# T113-S3 register map
Vendor: Allwinner; Series: T113-S3; File version: 0.1
CPU: other 0, little endian, MPU, no FPU, 0 interrupt priority bits
Registers are 32-bit, read-write, reset 0x0 unless marked. A register's access mark holds for its fields unless they carry their own. Offsets are from the block's base; [hi:lo] are bit positions; {n}, {i} and the like mark numbered series; 'fields as' and 'values as' point back to an identical list.

## OWA
Base 0x02036000
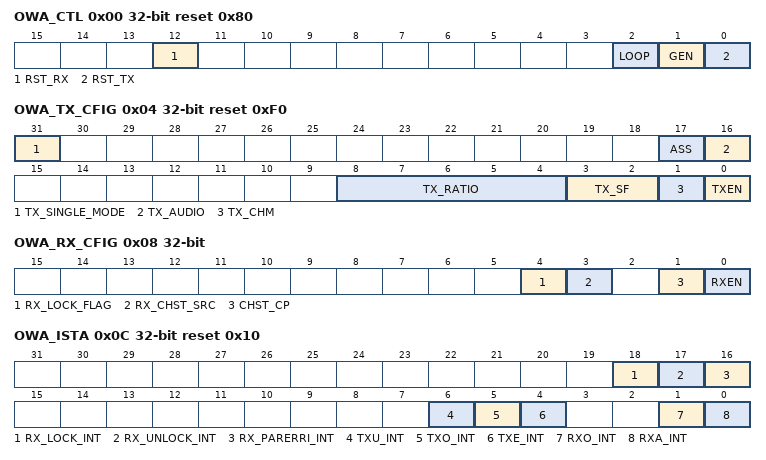
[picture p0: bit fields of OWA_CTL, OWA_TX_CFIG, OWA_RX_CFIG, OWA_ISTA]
0x00 OWA_CTL reset 0x80
  [12] RST_RX — Reset RX 0: Normal 1: Reset Self clear to `0`.
    0=Normal; 1=Reset Self clear to `0`
  [2] LOOP — Loopback Test 0: Normal Mode 1: Loopback Test When the bit is set to `1`, the DOUT and DIN need be connected.
    0=Normal Mode; 1=Loopback Test When the bit is set to `1`, the DOUT and DIN need be connected
  [1] GEN — Global Enable Disabling this bit overrides the operations of enabling and flushing all FIFOs by any other blocks or channels. 0: Disabled 1: Enabled
    0=Disabled; 1=Enabled
  [0] RST_TX — Reset TX 0: Normal 1: Reset Self clear to 0.
    0=Normal; 1=Reset Self clear to 0
0x04 OWA_TX_CFIG reset 0xF0 — OWA TX Configuration Register
  [31] TX_SINGLE_MODE — Tx Single Channel Mode 0: Disabled 1: Enabled
    0=Disabled; 1=Enabled
  [17] ASS — Audio Sample Select when TX FIFO Underrun 0: Sending 0 1: Sending the last audio
    0=Sending_0; 1=Sending the last audio
  [16] TX_AUDIO — TX Data Type 0: Linear PCM (Valid bit of both sub-frame set to 0 ) 1: Non-audio (Valid bit of both sub-frame set to 1)
    0=Linear PCM (Valid bit of both sub-frame set to 0 ); 1=Non-audio (Valid bit of both sub-frame set to 1)
  [8:4] TX_RATIO — TX Clock Divide Ratio Clock divide ratio = TX_TATIO + 1 Fs = PLL_AUDIO/[(TX_TATIO + 1)*64*2]
  [3:2] TX_SF — TX Sample Format 00: 16 bits 01: 20 bits 10: 24 bits 11: Reserved
    0=_16_bits; 1=_20_bits; 2=_24_bits
  [1] TX_CHM — CHSTMODE 0: Channel status A and B set to 0 1: Channel status A and B generated from TX_CHSTA
    0=Channel status A and B set to 0; 1=Channel status A and B generated from TX_CHSTA
  [0] TXEN — TX Enable 0: Disabled 1: Enabled
    0=Disabled; 1=Enabled
0x08 OWA_RX_CFIG — OWA RX Configuration Register
  [4] RX_LOCK_FLAG ro — RX Lock Flag 0: Unlocked 1: Locked
    0=Unlocked; 1=Locked
  [3] RX_CHST_SRC — RX Channel State Source Select 0: RX_CH_STA register holds status from Channel A 1: RX_CH_STA register holds status from Channel B
    0=RX_CH_STA_register_holds_status_from_Channel_A; 1=RX_CH_STA_register_holds_status_from_Channel_B
  [1] CHST_CP — Channel Status Capture 0: Idle or Capture End 1: Capture Channel Status Start The field must be set to 1 at each operation (such as recording). When set to `1`, the system starts to capture the channel status. When finished, the bit will automatically turn to `0`.
    0=Idle or Capture End; 1=Capture Channel Status Start The field must be set to 1 at each operation (such as recording). When set to `1`, the system starts to capture the channel status. When finished, the bit will automatically turn to `0`.
  [0] RXEN — 0: Disabled 1: Enabled
    0=Disabled; 1=Enabled
0x0C OWA_ISTA reset 0x10 — OWA Interrupt Status Register
  [18] RX_LOCK_INT write-1-clears — RX Lock Interrupt 0: No Pending IRQ 1: RX Lock Pending Interrupt (RX_LOCK_FLAG turns from 0 to 1) Write `1` to clear this interrupt.
    0=No Pending IRQ; 1=RX (RX Lock Pending Interrupt (RX_LOCK_FLAG turns from 0 to 1) Write `1` to clear this interrupt.)
  [17] RX_UNLOCK_INT write-1-clears — RX Unlock Pending Interrupt 0: No Pending IRQ 1: RX Unlock Pending Interrupt (RX_LOCK_FLAG turns from 0 to 1) Write 1 to clear this interrupt.
    0=No Pending IRQ; 1=RX (RX Unlock Pending Interrupt (RX_LOCK_FLAG turns from 0 to 1) Write 1 to clear this interrupt.)
  [16] RX_PARERRI_INT write-1-clears — RX Parity Error Pending Interrupt 0: No Pending IRQ 1: RX Parity Error Pending Interrupt Write `1` to clear this interrupt
    0=No Pending IRQ; 1=RX (RX Parity Error Pending Interrupt Write `1` to clear this interrupt)
  [6] TXU_INT write-1-clears — TX FIFO Underrun Pending Interrupt 0: No Pending IRQ 1: FIFO Underrun Pending Interrupt Writing `1` to clear this interrupt.
    0=No Pending IRQ; 1=FIFO (FIFO Underrun Pending Interrupt Writing `1` to clear this interrupt.)
  [5] TXO_INT write-1-clears — TX FIFO Overrun Pending Interrupt 0: No Pending IRQ 1: FIFO Overrun Pending Interrupt Writing `1` to clear this interrupt.
    0=No Pending IRQ; 1=FIFO (FIFO Overrun Pending Interrupt Writing `1` to clear this interrupt.)
  [4] TXE_INT write-1-clears — TX FIFO Empty Pending Interrupt 0: No Pending IRQ 1: FIFO Empty Pending Interrupt Writing `1` to clear this interrupt or automatically clear if the interrupt condition fails.
    0=No Pending IRQ; 1=FIFO (FIFO Empty Pending Interrupt Writing `1` to clear this interrupt or automatically clear if the interrupt condition fails.)
  [1] RXO_INT write-1-clears — RXFIFO Overrun Pending Interrupt 0: RXFIFO Overrun Pending Write `1` to clear this interrupt.
    0=RXFIFO (RXFIFO Overrun Pending Write `1` to clear this interrupt.)
  [0] RXA_INT write-1-clears — RXFIFO Available Pending Interrupt 0: No Pending IRQ 1: Data Available Pending IRQ Write `1` to clear this interrupt or automatically clear if the interrupt condition fails.
    0=No Pending IRQ; 1=Data Available Pending IRQ Write `1` to clear this interrupt or automatically clear if the interrupt condition fails
0x10 OWA_RXFIFO
  [31:0] RX_DATA ro — The host can get one sample by reading this register, A channel data is first, and then the B channel data.
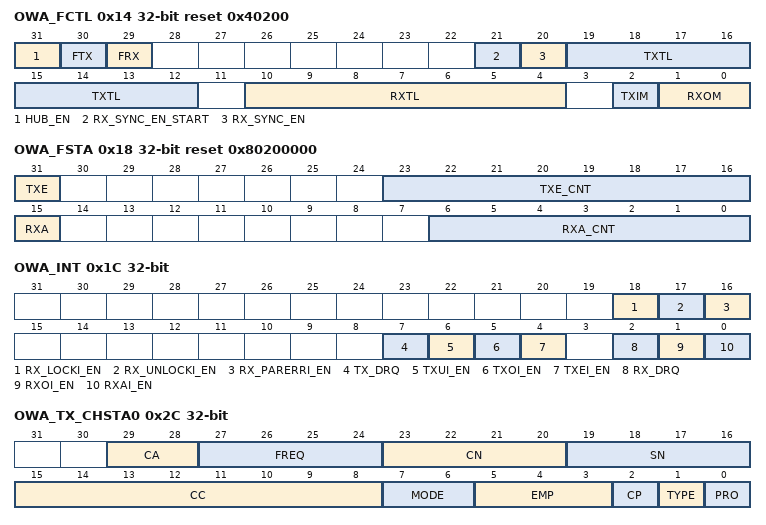
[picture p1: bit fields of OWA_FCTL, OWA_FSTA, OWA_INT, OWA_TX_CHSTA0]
0x14 OWA_FCTL reset 0x40200 — OWA FIFO Control Register
  [31] HUB_EN — Audio Hub Enable The bit takes effect only when the TXEN is set to 1. Audio codec/I2S1/I2S2/OWA TXFIFO Hub Enable. 0: Disabled 1: Enabled
    0=Disabled; 1=Enabled
  [30] FTX write-1-clears — Write `1` to flush TXFIFO, self clear to `0`.
  [29] FRX write-1-clears — Write `1` to flush RXFIFO, self clear to `0`.
  [21] RX_SYNC_EN_START — The bit takes effect only when the RX_SYNC_EN is set to 1. Audio Codec/I2S1/I2S2/DMIC/OWA RX Synchronize Enable Start. 0: Disabled 1: Enabled
    0=Disabled; 1=Enabled
  [20] RX_SYNC_EN — OWA RX Synchronize Enable 0: Disabled 1: Enabled
    0=Disabled; 1=Enabled
  [19:12] TXTL — TX FIFO Empty Trigger Level Interrupt and DMA request trigger level for TX FIFO normal condition. Trigger Level = TXTL
  [10:4] RXTL — RX FIFO Trigger Level Interrupt and DMA request trigger level for RX FIFO normal condition. Trigger Level = RXTL + 1
  [2] TXIM — TXFIFO Input Mode (Mode0, 1) 0: Valid data at the MSB of TXFIFO Register 1: Valid data at the LSB of TXFIFO Register Example for 20-bit transmitted audio sample: Mode 0: TXFIFO[23:0] = {APB_WDATA[31:12], 4`h0} Mode 1: TXFIFO[23:0] = {APB_WDATA[19:0], 4`h0}
    0=Valid data at the MSB of TXFIFO Register; 1=Valid data at the LSB of TXFIFO Register Example for 20-bit transmitted audio sample: Mode 0: TXFIFO[23:0] = {APB_WDATA[31:12], 4`h0} Mode 1: TXFIFO[23:0] = {APB_WDATA[19:0], 4`h0}
  [1:0] RXOM — RXFIFO Output Mode(Mode 0,1,2,3) 00: Expanding `0` at LSB of RXFIFO Register 01: Expanding received sample sign bit at MSB of RXFIFO Register 10: Truncating received samples at high half-word of RXFIFO Register and low half-word of RXFIFO Register is filled by `0` 11: Truncating received samples at low half-word of RXFIFO Register and high half-word of RXFIFO Register is expanded by its sigh bit Mode 0: APB_RDATA[31:0] = {RXFIFO[23:0], 8`h0} Mode 1: APB_RDATA[31:0] = {8`RXFIFO[23], RXFIFO[23:0]} Mode 2: APB_RDATA[31:0] = {RXFIFO[23:8], 16`h0} Mode 3: APB_RDATA[31:0] = {16`RXFIFO[23], RXFIFO[23:8]}
    0=Expanding `0` at LSB of RXFIFO Register; 1=Expanding received sample sign bit at MSB of RXFIFO Register; 2=Truncating received samples at high half-word of RXFIFO Register and low half-word of RXFIFO Register is filled by `0`; 3=Truncating received samples at low half-word of RXFIFO Register and high half-word of RXFIFO Register is expanded by its sigh bit Mode 0: APB_RDATA[31:0] = {RXFIFO[23:0], 8`h0} Mode 1: APB_RDATA[31:0] = {8`RXFIFO[23], RXFIFO[23:0]} Mode 2: APB_RDATA[31:0] = {RXFIFO[23:8], 16`h0} Mode 3: APB_RDATA[31:0] = {16`RXFIFO[23], RXFIFO[23:8]}
0x18 OWA_FSTA reset 0x80200000 — OWA FIFO Status Register
  [31] TXE ro — TXFIFO Empty (indicate the TXFIFO is not full) 0: No room for new sample in TXFIFO 1: More than one room for new sample in TXFIFO ( >= 1 Word )
    0=No room for new sample in TXFIFO; 1=More than one room for new sample in TXFIFO ( >= 1 Word )
  [23:16] TXE_CNT ro — TXFIFO Empty Space Word Counter
  [15] RXA ro — RXFIFO Available 0: No available data in RXFIFO 1: More than one sample in RXFIFO ( >= 1 Word )
    0=No available data in RXFIFO; 1=More than one sample in RXFIFO ( >= 1 Word )
  [6:0] RXA_CNT ro — RXFIFO Available Sample Word Counter
0x1C OWA_INT — OWA Interrupt Control Register
  [all] fields
    0=Disabled; 1=Enabled
  [18] RX_LOCKI_EN — RX LOCK Interrupt Enable 0: Disabled 1: Enabled
  [17] RX_UNLOCKI_EN — RX UNLOCK Interrupt Enable 0: Disabled 1: Enabled
  [16] RX_PARERRI_EN — RX PARITY ERORR Interrupt Enable 0: Disabled 1: Enabled
  [7] TX_DRQ — TXFIFO Empty DRQ Enable 0: Disabled 1: Enabled
  [6] TXUI_EN — TXFIFO Underrun Interrupt Enable 0: Disabled 1: Enabled
  [5] TXOI_EN — TXFIFO Overrun Interrupt Enable 0: Disabled 1: Enabled
  [4] TXEI_EN — TXFIFO Empty Interrupt Enable 0: Disabled 1: Enabled
  [2] RX_DRQ — RXFIFO Data Available DRQ Enable When set to `1`, RXFIFO DMA Request is asserted if data is available in RXFIFO. 0: Disabled 1: Enabled
  [1] RXOI_EN — RXFIFO Overrun Interrupt Enable 0: Disabled 1: Enabled
  [0] RXAI_EN — RXFIFO Data Available Interrupt Enable 0: Disabled 1: Enabled
0x20 OWA_TXFIFO
  [31:0] TX_DATA wo — Transmitting A, B channel data should be written this register one by one. A channel data is first, and then the B channel data.
0x24 OWA_TX_CNT — OWA TX Counter Register
  [31:0] TX_CNT — TX Sample Counter The audio sample number of sending into TXFIFO. When one sample is put into TXFIFO by DMA or by host IO, the TX sample counter register increases by one. The TX sample counter register can be set to any initial value at any time. After updated by the initial value, the counter register should count on the base of this initial value.
0x28 OWA_RX_CNT — OWA RX Counter Register
  [31:0] RX_CNT — RX Sample Counter The audio sample number of writing into RXFIFO. When one sample is written by Codec, the RX sample counter register increases by one. The RX counter register can be set to any initial value at any time. After being updated by the initial value, the counter register should count on the base of this value.
0x2C OWA_TX_CHSTA0 — OWA TX Channel Status Register0
  [29:28] CA — Clock Accuracy 00: Level 2 01: Level 1 10: Level 3 11: Not matched
    0=Level_2; 1=Level_1; 2=Level_3; 3=Not_matched
  [27:24] FREQ — Sampling Frequency 0000: 44.1 kHz 0001: Not indicated 0010: 48 kHz 0011: 32 kHz 0100: 22.05 kHz 0101: Reserved 0110: 24 kHz 0111: Reserved 1000: Reserved 1001: 768 kHz 1010: 96 kHz 1011: Reserved 1100: 176.4 kHz 1101: Reserved 1110: 192 kHz 1111: Reserved
    0=_44_point_1_kHz (44.1 kHz); 1=Not_indicated; 2=_48_kHz; 3=_32_kHz; 4=_22_point_05_kHz (22.05 kHz); 6=_24_kHz; 9=_768_kHz; 10=_96_kHz; 12=_176_point_4_kHz (176.4 kHz); 14=_192_kHz
  [23:20] CN — Channel Number
  [19:16] SN — Source Number
  [15:8] CC — Category Code Indicates the kind of equipment that generates the digital audio interface signal.
  [7:6] MODE — Mode 00: Default Mode 01 to 11: Reserved
    0=Default Mode 01 to 11: Reserved
  [5:3] EMP — Emphasis Additional format information For bit 1 = `0`, Linear PCM audio mode: 000: 2 audio channels without pre-emphasis 001: 2 audio channels with 50 μs/15 μs pre-emphasis 010: Reserved (for 2 audio channels with pre-emphasis) 011: Reserved (for 2 audio channels with pre-emphasis) 100 to 111: Reserved For bit 1 = `1`, other than Linear PCM applications: 000: Default state 001 to 111: Reserved
  [2] CP — Copyright 0: Copyright is asserted 1: No copyright is asserted
    0=Copyright is asserted; 1=No copyright is asserted
  [1] TYPE — Audio Data Type 0: Linear PCM samples 1: Non-linear PCM audio
    0=Linear PCM samples; 1=Non-linear PCM audio
  [0] PRO — Application Type 0: Consumer application 1: Professional application This bit must be fixed to `0`.
    0=Consumer application; 1=Professional application This bit must be fixed to `0`
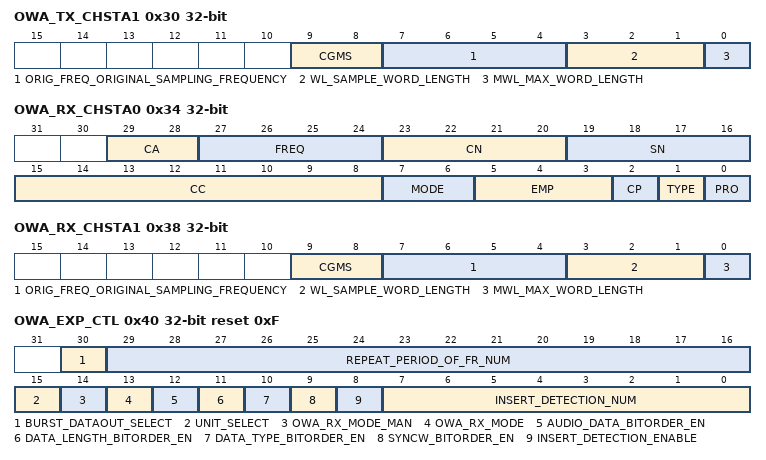
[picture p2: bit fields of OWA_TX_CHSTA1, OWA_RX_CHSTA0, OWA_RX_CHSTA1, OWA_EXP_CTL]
0x30 OWA_TX_CHSTA1 — OWA TX Channel Status Register1
  [9:8] CGMS — CGMS_A 00: Copying is permitted without restriction 01: One generation of copies may be made 10: Condition not be used 11: No copying is permitted
    0=Copying is permitted without restriction; 1=One (One generation of copies may be made); 2=Condition not be used; 3=No copying is permitted
  [7:4] ORIG_FREQ_ORIGINAL_SAMPLING_FREQUENCY — ORIG_FREQ Original Sampling Frequency 0000: Not indicated 0001: 192 kHz 0010: 12 kHz 0011: 176.4 kHz 0100: Reserved 0101: 96 kHz 0110: 8 kHz 0111: 88.2 kHz 1000: 16 kHz 1001: 24 kHz 1010: 11.025 kHz 1011: 22.05 kHz 1100: 32 kHz 1101: 48 kHz 1110: Reserved 1111: 44.1 kHz
    0=Not_indicated; 1=_192_kHz; 2=_12_kHz; 3=_176_point_4_kHz (176.4 kHz); 5=_96_kHz; 6=_8_kHz; 7=_88_point_2_kHz (88.2 kHz); 8=_16_kHz; 9=_24_kHz; 10=_11_point_025_kHz (11.025 kHz); 11=_22_point_05_kHz (22.05 kHz); 12=_32_kHz; 13=_48_kHz; 15=_44_point_1_kHz (44.1 kHz)
  [3:1] WL_SAMPLE_WORD_LENGTH — WL Sample Word Length For bit 0 = `0`: 000: Not indicated 001: 16 bits 010: 18 bits 100: 19 bits 101: 20 bits 110: 17 bits 111: Reserved For bit 0 = `1`: 000: Not indicated 001: 20 bits 010: 22 bits 100: 23 bits 101: 24 bits 110: 21 bits 111: Reserved
  [0] MWL_MAX_WORD_LENGTH — MWL Max Word Length 0: Maximum audio sample word length is 20 bits 1: Maximum audio sample word length is 24 bits
    0=Maximum audio sample word length is 20 bits; 1=Maximum audio sample word length is 24 bits
0x34 OWA_RX_CHSTA0
  [29:28] CA — Clock Accuracy 00: Level 2 01: Level 1 10: Level 3 11: Not Matched
    0=Level_2; 1=Level_1; 2=Level_3; 3=Not_Matched
  [27:24] FREQ — Sampling Frequency 0000: 44.1 kHz 0001: Not Indicated 0010: 48 kHz 0011: 32 kHz 0100: 22.05 kHz 0101: Reserved 0110: 24 kHz 0111: Reserved 1000: Reserved 1001: 768 kHz 1010: 96 kHz 1011: Reserved 1100: 176.4 kHz 1101: Reserved 1110: 192 kHz 1111: Reserved
    0=_44_point_1_kHz (44.1 kHz); 1=Not_Indicated; 2=_48_kHz; 3=_32_kHz; 4=_22_point_05_kHz (22.05 kHz); 6=_24_kHz; 9=_768_kHz; 10=_96_kHz; 12=_176_point_4_kHz (176.4 kHz); 14=_192_kHz
  [23:20] CN — Channel Number
  [19:16] SN — Source Number
  [15:8] CC — Category Code Indicates the Kind of Equipment that Generates the digital audio interface Signal.
  [7:6] MODE — Mode 00: Default mode 01 to 11: Reserved
    0=Default mode 01 to 11: Reserved
  [5:3] EMP — Emphasis Additional Format Information For bit 1 = `0`, Linear PCM Audio mode: 000: 2 Audio channels without pre-emphasis 001: 2 Audio channels with 50 μs/15 μs pre-emphasis 010: Reserved (For 2 Audio channels with pre-emphasis) 011: Reserved (For 2 Audio channels with pre-emphasis) 100 to 111: Reserved For bit 1 = `1`, Other than Linear PCM applications: 000: Default state 001 to 111: Reserved
  [2] CP — Copyright 0: Copyright is asserted 1: No Copyright is asserted
    0=Copyright is asserted; 1=No Copyright is asserted
  [1] TYPE — Audio Data Type 0: Linear PCM samples 1: Non-linear PCM audio
    0=Linear PCM samples; 1=Non-linear PCM audio
  [0] PRO — Application Type 0: Consumer application 1: Professional application
    0=Consumer application; 1=Professional application
0x38 OWA_RX_CHSTA1
  [9:8] CGMS — CGMS_A 00: Copying is permitted without restriction 01: One generation of copies may be made 10: Condition is not be used 11: No copying is permitted
    0=Copying is permitted without restriction; 1=One (One generation of copies may be made); 2=Condition is not be used; 3=No copying is permitted
  [7:4] ORIG_FREQ_ORIGINAL_SAMPLING_FREQUENCY — ORIG_FREQ Original Sampling Frequency 0000: Not indicated 0001: 192 kHz 0010: 12 kHz 0011: 176.4 kHz 0100: Reserved 0101: 96 kHz 0110: 8 kHz 0111: 88.2 kHz 1000: 16 kHz 1001: 24 kHz 1010: 11.025 kHz 1011: 22.05 kHz 1100: 32 kHz 1101: 48 kHz 1110: Reserved 1111: 44.1 kHz
    values as OWA_TX_CHSTA1.ORIG_FREQ_ORIGINAL_SAMPLING_FREQUENCY
  [3:1] WL_SAMPLE_WORD_LENGTH — WL Sample Word Length For bit 0 = `0`: 000: Not indicated 001: 16 bits 010: 18 bits 100: 19 bits 101: 20 bits 110: 17 bits 111: Reserved For bit 0 = `1`: 000: Not indicated 001: 20 bits 010: 22 bits 100: 23 bits 101: 24 bits 110: 21 bits 111: Reserved
  [0] MWL_MAX_WORD_LENGTH — MWL Max Word Length 0: Maximum Audio sample word length is 20 bits 1: Maximum Audio sample word length is 24 bits
    0=Maximum Audio sample word length is 20 bits; 1=Maximum Audio sample word length is 24 bits
0x40 OWA_EXP_CTL reset 0xF — OWA Expand Control Register
  [30] BURST_DATAOUT_SELECT — Burst data output select 0: Burst preamble and payload 1: Burst payload
    0=Burst preamble and payload; 1=Burst_payload
  [29:16] REPEAT_PERIOD_OF_FR_NUM — The number for the repetition period of the burst frame Configure this field according to RX data. A mismatch between the configuration data and the received data will result in an error interrupt.
  [15] UNIT_SELECT — Unit Select Configure this field according to RX data type 0: In units of 16-bit 1: In units of 2-byte
    0=In_units_of_16_bit; 1=In_units_of_2_byte
  [14] OWA_RX_MODE_MAN — OWA RX Proteocol Select 0: IEC60958 1: IEC61937
    0=IEC60958; 1=IEC61937
  [13] OWA_RX_MODE — OWA RX Mode Select 0: Manual Ctrl. Configure by OWA_RX_MODE_MAN 1: Auto Ctrl. Configure by the channel status values resolved by hardware
    0=Manual Ctrl. Configure by OWA_RX_MODE_MAN; 1=Auto Ctrl. Configure by the channel status values resolved by hardware
  [12] AUDIO_DATA_BITORDER_EN — Audio data bitorder enable 0: The audio data received by RX is stored directly into FIFO 1: The audio data received by RX is reversed high and low bits, then stored into FIFO
    0=stored (The audio data received by RX is stored directly into FIFO); 1=reversed (The audio data received by RX is reversed high and low bits, then stored into FIFO)
  [11] DATA_LENGTH_BITORDER_EN — Data length bitorder enable 0: The received PD data is as the length of the valid audio data 1: The received PD data is reversed high and low bits, then as the length of the valid audio data
    0=as (The received PD data is as the length of the valid audio data); 1=reversed (The received PD data is reversed high and low bits, then as the length of the valid audio data)
  [10] DATA_TYPE_BITORDER_EN — Data type bitorder enable 0: The received PC data is as the data length of the valid audio 1: The received PC data is reversed high and low bits, then as the length of the valid audio data
    0=as (The received PC data is as the data length of the valid audio); 1=reversed (The received PC data is reversed high and low bits, then as the length of the valid audio data)
  [9] SYNCW_BITORDER_EN — Syncw_bitorder_en 0: Pa/Pb is the sync code of audio data 1: Pa/Pb reversed high and low bits is the sync code of audio data
    0=the_sync (Pa/Pb is the sync code of audio data); 1=Pa_slash_Pb_reversed (Pa/Pb reversed high and low bits is the sync code of audio data)
  [8] INSERT_DETECTION_ENABLE — Insert detection enable 0: Disable 1: Enable
    0=Disable; 1=Enable
  [7:0] INSERT_DETECTION_NUM — Insert detection number Configure how many jumping edges are detected to generate an insertion interrupt
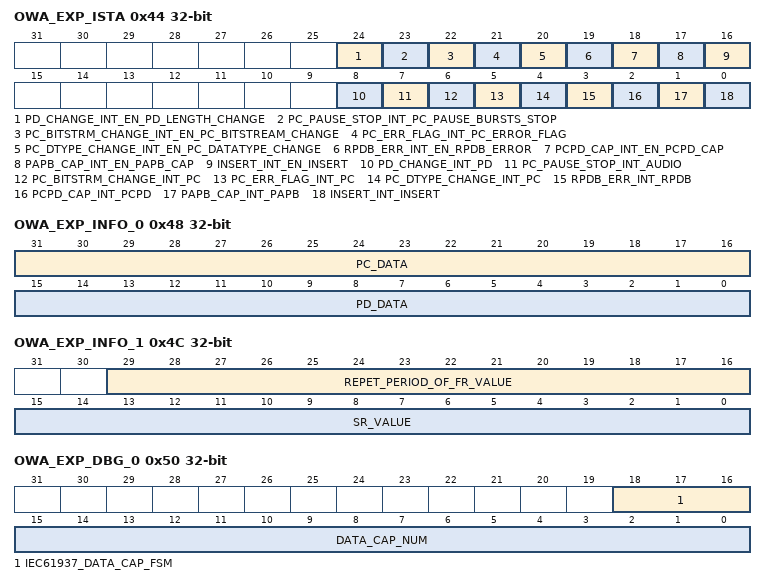
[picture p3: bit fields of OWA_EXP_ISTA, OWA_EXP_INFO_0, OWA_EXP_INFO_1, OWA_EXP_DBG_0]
0x44 OWA_EXP_ISTA — OWA Expand Interrupt Status Register
  [24] PD_CHANGE_INT_EN_PD_LENGTH_CHANGE — PD_CHANGE_INT_EN PD_LENGTH_CHANGE Interrupt Enable 0: Disable 1: Enable
    0=Disable; 1=Enable
  [23] PC_PAUSE_STOP_INT_PC_PAUSE_BURSTS_STOP — PC_PAUSE_STOP_INT PC_PAUSE_BURSTS_STOP Interrupt Enable 0: Disable 1: Enable
    0=Disable; 1=Enable
  [22] PC_BITSTRM_CHANGE_INT_EN_PC_BITSTREAM_CHANGE — PC_BITSTRM_CHANGE_INT_EN PC_BITSTREAM_CHANGE Interrupt Enable 0: Disable 1: Enable
    0=Disable; 1=Enable
  [21] PC_ERR_FLAG_INT_PC_ERROR_FLAG — PC_ERR_FLAG_INT PC_ERROR_FLAG Interrupt Enable 0: Disable 1: Enable
    0=Disable; 1=Enable
  [20] PC_DTYPE_CHANGE_INT_EN_PC_DATATYPE_CHANGE — PC_DTYPE_CHANGE_INT_EN PC_DATATYPE_CHANGE Interrupt Enable 0: Disable 1: Enable
    0=Disable; 1=Enable
  [19] RPDB_ERR_INT_EN_RPDB_ERROR — RPDB_ERR_INT_EN RPDB_ERROR Interrupt Enable 0: Disable 1: Enable
    0=Disable; 1=Enable
  [18] PCPD_CAP_INT_EN_PCPD_CAP — PCPD_CAP_INT_EN PCPD_CAP Interrupt Enable 0: Disable 1: Enable
    0=Disable; 1=Enable
  [17] PAPB_CAP_INT_EN_PAPB_CAP — PAPB_CAP_INT_EN PAPB_CAP Interrupt Enable 0: Disable 1: Enable
    0=Disable; 1=Enable
  [16] INSERT_INT_EN_INSERT — INSERT_INT_EN INSERT Interrupt Enable 0: Disable 1: Enable
    0=Disable; 1=Enable
  [8] PD_CHANGE_INT_PD write-1-clears — PD_CHANGE_INT PD CHANGE INT 0: No Pending IRQ 1: PD Data length information is change. (except Pause/Null data burst type) Write `1` to clear this interrupt.
    0=No Pending IRQ; 1=PD (PD Data length information is change. (except Pause/Null data burst type) Write `1` to clear this interrupt.)
  [7] PC_PAUSE_STOP_INT_AUDIO write-1-clears — PC_PAUSE_STOP_INT Audio bitstream is interrupted. When stopped, the interface becomes idle. 0: No Pending IRQ 1: PC Pause burst Stop, frame sequence discontinued. Transmitters may optionally use the STOP value to indicate that the transmission of the current encoded Write `1` to clear this interrupt.
    0=No Pending IRQ; 1=PC (PC Pause burst Stop, frame sequence discontinued. Transmitters may optionally use the STOP value to indicate that the transmission of the current encoded Write `1` to clear this interrupt.)
  [6] PC_BITSTRM_CHANGE_INT_PC write-1-clears — PC_BITSTRM_CHANGE_INT PC BITSTRM CHANGE INT 0: No Pending IRQ 1: PC Bitstream Number is change. Bitstream Number indicates which bitstream the data burst belongs. (except Pause/Null data bursts type ) Write `1` to clear this interrupt.
    0=No Pending IRQ; 1=PC (PC Bitstream Number is change. Bitstream Number indicates which bitstream the data burst belongs. (except Pause/Null data bursts type ) Write `1` to clear this interrupt.)
  [5] PC_ERR_FLAG_INT_PC write-1-clears — PC_ERR_FLAG_INT PC ERR FLAG INT 0: No Pending IRQ 1: PC Error-flag is available to indicate if the contents of the data- burst contain data errors (except Pause/Null data bursts type) . The using of this bit by receivers is optional. Write `1` to clear this interrupt.
    0=No Pending IRQ; 1=PC (PC Error-flag is available to indicate if the contents of the data- burst contain data errors (except Pause/Null data bursts type) . The using of this bit by receivers is optional. Write `1` to clear this interrupt.)
  [4] PC_DTYPE_CHANGE_INT_PC write-1-clears — PC_DTYPE_CHANGE_INT PC DTYPE CHANGE INT 0: No Pending IRQ 1: PC Datatype (except Pause/Null data type) information is change Write `1` to clear this interrupt.
    0=No Pending IRQ; 1=PC (PC Datatype (except Pause/Null data type) information is change Write `1` to clear this interrupt.)
  [3] RPDB_ERR_INT_RPDB write-1-clears — RPDB_ERR_INT RPDB ERR INT 0: No Pending IRQ 1: Hardware counts the repetition period of the burst frame is different from register configuration number Write `1` to clear this interrupt.
    0=No Pending IRQ; 1=Hardware counts the repetition period of the burst frame is different from register configuration number Write `1` to clear this interrupt
  [2] PCPD_CAP_INT_PCPD write-1-clears — PCPD_CAP_INT PCPD CAP INT 0: No Pending IRQ 1: IEC61937 mode captures PC and PD Write `1` to clear this interrupt.
    0=No Pending IRQ; 1=IEC61937 mode captures PC and PD Write `1` to clear this interrupt
  [1] PAPB_CAP_INT_PAPB write-1-clears — PAPB_CAP_INT PAPB CAP INT 0: No Pending IRQ 1: IEC61937 mode captures PA and PB Write `1` to clear this interrupt.
    0=No Pending IRQ; 1=IEC61937 mode captures PA and PB Write `1` to clear this interrupt
  [0] INSERT_INT_INSERT write-1-clears — INSERT_INT INSERT INT 0: No Pending IRQ 1: OWA RX detects device insertion Write `1` to clear this interrupt.
    0=No Pending IRQ; 1=OWA (OWA RX detects device insertion Write `1` to clear this interrupt.)
0x48 OWA_EXP_INFO_0 — OWA Expand Infomation Register0
  [31:16] PC_DATA ro — PC Data information
  [15:0] PD_DATA ro — PD Data information
0x4C OWA_EXP_INFO_1 — OWA Expand Infomation Register1
  [29:16] REPET_PERIOD_OF_FR_VALUE ro — Repetition period of the burst frame value Check whether the repetition period of the burst frame calculated by hardware is consistent with the configuration value.
  [15:0] SR_VALUE ro — Sample Rate Value Read this value after RX_LOCK.
0x50 OWA_EXP_DBG_0 — OWA Expand Debug Register0
  [18:16] IEC61937_DATA_CAP_FSM ro — IEC61937 Data Captures State Machine 000: IDLE 001: SYNC_PA 010: SYNC_PB 011: DTYPE_PC 100: DLEN_PD 101: RX_ACTIVE
    0=IDLE; 1=SYNC_PA; 2=SYNC_PB; 3=DTYPE_PC; 4=DLEN_PD; 5=RX_ACTIVE
  [15:0] DATA_CAP_NUM ro — Remains Data Counter Value See the value of the sampled valid data in real time.
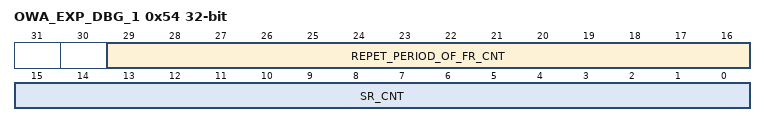
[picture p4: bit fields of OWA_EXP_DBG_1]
0x54 OWA_EXP_DBG_1 — OWA Expand Debug Register1
  [29:16] REPET_PERIOD_OF_FR_CNT ro — Repetition period of the burst frame counter See the value of repetition period counter in real time.
  [15:0] SR_CNT ro — Sample Rate Counter See the value of audio sample ratio in real time.
